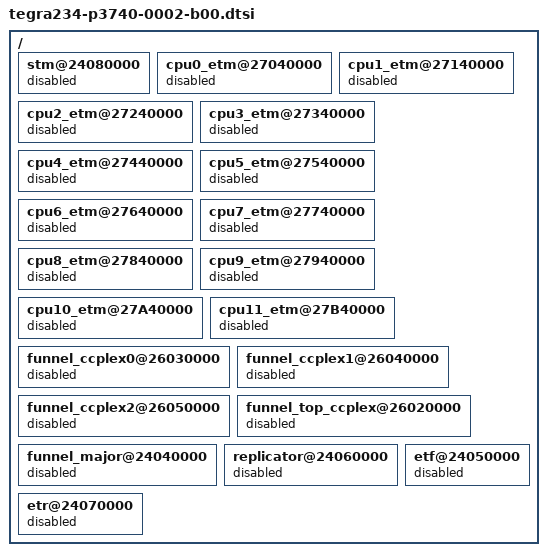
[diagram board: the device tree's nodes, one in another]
/*
 * Copyright (c) 2022, NVIDIA CORPORATION.  All rights reserved.
 *
 * This program is free software; you can redistribute it and/or modify
 * it under the terms of the GNU General Public License as published by
 * the Free Software Foundation; version 2 of the License.
 *
 * This program is distributed in the hope that it will be useful, but WITHOUT
 * ANY WARRANTY; without even the implied warranty of MERCHANTABILITY or
 * FITNESS FOR A PARTICULAR PURPOSE.  See the GNU General Public License for
 * more details.
 */

#include <dt-bindings/gpio/tegra234-gpio.h>
#include <dt-bindings/input/input.h>
#include "tegra234-p3740-b00-fixed-regulator.dtsi"

/ {
	stm@24080000 {
		status = "disabled";
	};

	cpu0_etm@27040000 {
		status = "disabled";
	};

	cpu1_etm@27140000 {
		status = "disabled";
	};

	cpu2_etm@27240000 {
		status = "disabled";
	};

	cpu3_etm@27340000 {
		status = "disabled";
	};

	cpu4_etm@27440000 {
		status = "disabled";
	};

	cpu5_etm@27540000 {
		status = "disabled";
	};

	cpu6_etm@27640000 {
		status = "disabled";
	};

	cpu7_etm@27740000 {
		status = "disabled";
	};

	cpu8_etm@27840000 {
		status = "disabled";
	};

	cpu9_etm@27940000 {
		status = "disabled";
	};

	cpu10_etm@27A40000 {
		status = "disabled";
	};

	cpu11_etm@27B40000 {
		status = "disabled";
	};

	funnel_ccplex0@26030000 {
		status = "disabled";
	};

	funnel_ccplex1@26040000 {
		status = "disabled";
	};

	funnel_ccplex2@26050000 {
		status = "disabled";
	};

	funnel_top_ccplex@26020000 {
		status = "disabled";
	};

	funnel_major@24040000 {
		status = "disabled";
	};

	replicator@24060000 {
		status = "disabled";
	};

	etf@24050000 {
		status = "disabled";
	};

	etr@24070000 {
		status = "disabled";
	};
};
